# ML630Q466 register map
Vendor: LAPIS Semiconductor Co.,Ltd.; File version: 1.00
ARM Cortex-M0+ based Microcontroller 'ML630Q466' device of LAPIS Semiconductor Co., Ltd.
CPU: CM0PLUS r0p1, little endian, no MPU, no FPU, 2 interrupt priority bits
Registers are 32-bit, read-write, no defined reset value unless marked. A register's access mark holds for its fields unless they carry their own. Offsets are from the block's base; lines under a group give offsets from that group; [hi:lo] are bit positions; {n}, {i} and the like mark numbered series; 'fields as' and 'values as' point back to an identical list; <NAME> marks a mode.

## Memory map
0x40000400 FLASHCNT size 0x28 — Flash controller
0x40001000 AES size 0x7C
0x40001800 RND size 0x8
0x41000000 SSIO0 size 0xC
0x41000800 SSIOF0 size 0x24
0x41001000 UART0 size 0x3C
0x41001800 UARTF0 size 0x18
0x41002000 I2C1 size 0x18
0x41002800 I2CF0 size 0x54
0x41004000 USBDEV size 0x1F8
0x42000000 RADC size 0x44
0x42001000 SADC size 0x64
0x43000000 LCDCNT size 0x1000
0x47000000 DMAC size 0xC
0x47000100 DMAC0 size 0x18
0x47000200 DMAC1 size 0x18
0x5C000000 LSICNT size 0x64
0x5C000100 NINT size 0x14
0x5C000200 RESET size 0x8
0x5C000300 CLKCNT size 0x14
0x5C001000 TIMER size 0xFC
0x5C002000 WDT size 0x8
0x5C002100 LTBC size 0x10
0x5C002200 TIMER1K size 0x8
0x5C002300 RTC size 0x64
0x5C003000 FTIMER size 0xF10
0x5C004000 PORT0 size 0x10
0x5C004200 PORT2 size 0x10
0x5C004300 PORT3 size 0x10
0x5C004400 PORT4 size 0x10
0x5C004500 PORT5 size 0x10
0x5C004600 PORT6 size 0x10
0x5C005000 VLS size 0x8
0x5C005100 CMP size 0xA4

## Interrupts
0 EXI (PORT0)
1 TM0 (TIMER)
2 TM1 (TIMER)
3 FTM0 (FTIMER)
4 DMAC0
5 AES
6 SIO0 (SSIO0)
7 I2C1
8 UA0 (UART0)
9 TM2 (TIMER)
10 TM3 (TIMER)
11 FTM1 (FTIMER)
12 DMAC1
13 CMP
14 SIOF0 (SSIOF0)
15 I2CF0
16 UAF0 (UARTF0)
17 TM4 (TIMER)
18 TM5 (TIMER)
19 FTM2 (FTIMER)
20 LOSC (CLKCNT)
21 VLS
22 SAD (SADC)
23 RAD (RADC)
24 USB (USBDEV)
25 TM6 (TIMER)
26 TM7 (TIMER)
27 FTM3 (FTIMER)
28 RTC
29 LTBC
30 TM1K (TIMER1K)

## FLASHCNT — Flash controller
Base 0x40000400
0x00 FLCSTA ro — Flashcnt status register
  [0] BUSY — Busy bit
    1=busy
0x04 FLCACP wo — Flashcnt accept register
  [7:0] FAC
0x08 FLCADR — Flashcnt address register
  [31:2] FA
0x0C FLCWDA wo — Flashcnt write data register
  [31:0] FD
0x10 FLCERA — Flashcnt erase register
  [1:0] FLE
    1=Chip erase; 2=Block erase; 3=Sector erase
0x20 FLCRSIZ ro — Flashcnt size register
  [31:0] FSI
0x24 FLCBADR ro — Flashcnt boot program address register
  [17:2] BPA

## AES
Base 0x40001000
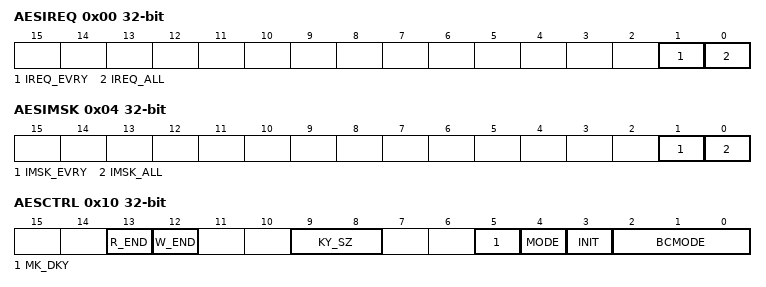
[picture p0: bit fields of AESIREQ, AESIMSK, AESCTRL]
0x00 AESIREQ
  [1] IREQ_EVRY, [0] IREQ_ALL
0x04 AESIMSK
  [1] IMSK_EVRY, [0] IMSK_ALL
0x08 AESSTRT
  [7:0] STRT_REQ_CNT
0x0C AESSTAT ro
  [0] STRT_EN
0x10 AESCTRL
  [13] R_END, [12] W_END, [9:8] KY_SZ, [5] MK_DKY, [4] MODE, [3] INIT, [2:0] BCMODE
{0x14+4i} AESIVC{i} (i=0..3)
  [31:0] IVC
{0x24+4i} AESBFT{i} (i=0..3)
  [31:0] BFT
{0x34+4i} AESAFT{i} ro (i=0..3)
  [31:0] AFT
{0x44+4i} AESEKY{i} wo (i=0..7)
  [31:0] EKY

## RND
Base 0x40001800
0x00 RNDDT ro
  [7:0] D
0x04 RNDEN
  [0] EN

## SSIO0
Base 0x41000000
0x00 SIO0BUF — Serial port 0 transmit/receive buffer
  [15:0] S0B
0x04 SIO0CON — Serial port 0 control register
  [0] S0EN
    0=Stop; 1=Start
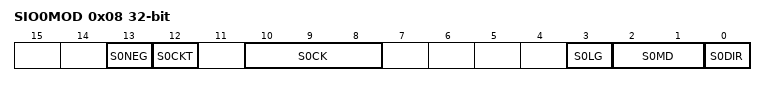
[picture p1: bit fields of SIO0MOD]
0x08 SIO0MOD access per field — Serial port 0 mode register
  [13] S0NEG rw, [12] S0CKT rw, [10:8] S0CK rw, [3] S0LG rw, [2:1] S0MD wo, [0] S0DIR rw

## Licence text in the file
This software is provided "as is" and any expressed or implied warranties, including, but not limited to, the implied warranties of merchantability and fitness for a particular purpose are disclaimed. LAPIS Semiconductor shall not be liable for any direct, indirect, consequential or incidental damages arising from using or modifying this software. You (customer) can modify and use this software in whole or part on your own responsibility, only for the purpose of developing the software for use with microcontroller manufactured by LAPIS Semiconductor.
